AUTOSAR XML (schema 00049)
package /Components
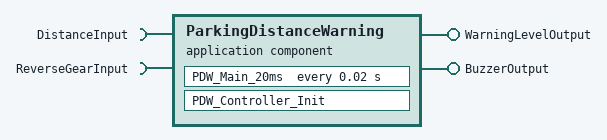
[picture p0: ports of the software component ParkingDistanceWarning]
  application sw component type ParkingDistanceWarning
    require port DistanceInput: nonqueued-receiver-com-spec{data-element=DistanceInput, init-value=0}, required-interface=DistanceInput
    require port ReverseGearInput: nonqueued-receiver-com-spec{data-element=ReverseGearInput, init-value=0}, required-interface=ReverseGearInput
    provide port WarningLevelOutput: nonqueued-sender-com-spec{data-element=WarningLevelOutput, init-value=0}, provided-interface=WarningLevelOutput
    provide port BuzzerOutput: nonqueued-sender-com-spec{data-element=BuzzerOutput, init-value=0}, provided-interface=BuzzerOutput
    behavior PDW_Controller_IB: handle-termination-and-restart=NO-SUPPORT
      timing event PDW_Timing_20ms: start-on-event=PDW_Main_20ms, period=0.02
      runnable PDW_Controller_Init
      runnable PDW_Main_20ms
        data-read-access:
          access IN_DistanceInput_DistanceInput: accessed-variable=DistanceInput.DistanceInput
          access IN_ReverseGearInput_ReverseGearInput: accessed-variable=ReverseGearInput.ReverseGearInput
        data-write-access:
          access OUT_WarningLevelOutput_WarningLevelOutput: accessed-variable=WarningLevelOutput.WarningLevelOutput
          access OUT_BuzzerOutput_BuzzerOutput: accessed-variable=BuzzerOutput.BuzzerOutput
